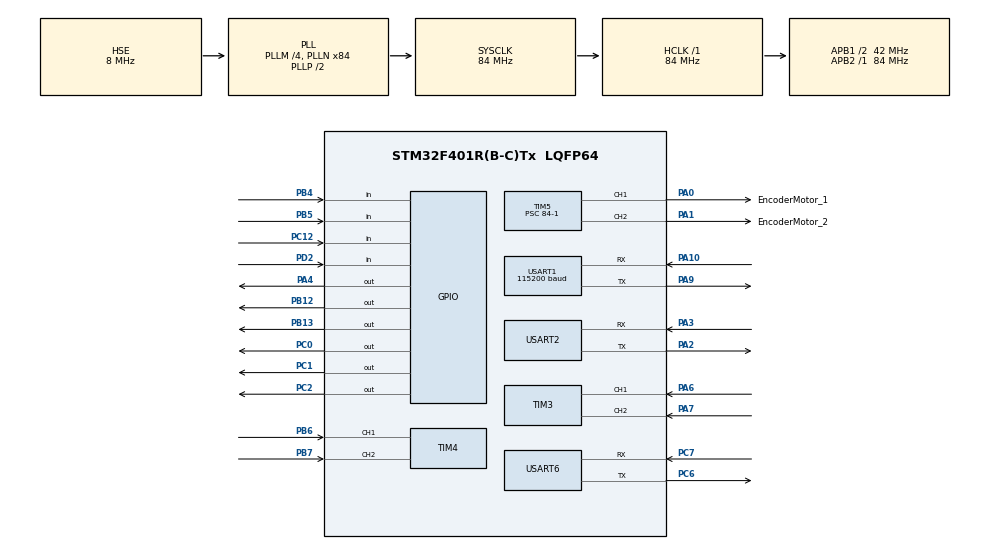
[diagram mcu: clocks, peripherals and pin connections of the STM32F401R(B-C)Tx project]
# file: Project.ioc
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Dma.Request0=USART2_RX
Dma.Request1=USART6_RX
Dma.Request2=USART1_RX
Dma.Request3=USART1_TX
Dma.USART1_RX.2.Direction=DMA_PERIPH_TO_MEMORY
Dma.USART1_RX.2.FIFOMode=DMA_FIFOMODE_DISABLE
Dma.USART1_RX.2.Instance=DMA2_Stream2
Dma.USART1_RX.2.MemDataAlignment=DMA_MDATAALIGN_BYTE
Dma.USART1_RX.2.MemInc=DMA_MINC_ENABLE
Dma.USART1_RX.2.Mode=DMA_NORMAL
Dma.USART1_RX.2.PeriphDataAlignment=DMA_PDATAALIGN_BYTE
Dma.USART1_RX.2.PeriphInc=DMA_PINC_DISABLE
Dma.USART1_RX.2.Priority=DMA_PRIORITY_LOW
Dma.USART1_TX.3.Direction=DMA_MEMORY_TO_PERIPH
Dma.USART1_TX.3.FIFOMode=DMA_FIFOMODE_DISABLE
Dma.USART1_TX.3.Instance=DMA2_Stream7
Dma.USART1_TX.3.MemDataAlignment=DMA_MDATAALIGN_BYTE
Dma.USART1_TX.3.MemInc=DMA_MINC_ENABLE
Dma.USART1_TX.3.Mode=DMA_NORMAL
Dma.USART1_TX.3.PeriphDataAlignment=DMA_PDATAALIGN_BYTE
Dma.USART1_TX.3.PeriphInc=DMA_PINC_DISABLE
Dma.USART1_TX.3.Priority=DMA_PRIORITY_LOW
Dma.USART2_RX.0.Direction=DMA_PERIPH_TO_MEMORY
Dma.USART2_RX.0.FIFOMode=DMA_FIFOMODE_DISABLE
Dma.USART2_RX.0.Instance=DMA1_Stream5
Dma.USART2_RX.0.MemDataAlignment=DMA_MDATAALIGN_BYTE
Dma.USART2_RX.0.MemInc=DMA_MINC_ENABLE
Dma.USART2_RX.0.Mode=DMA_NORMAL
Dma.USART2_RX.0.PeriphDataAlignment=DMA_PDATAALIGN_BYTE
Dma.USART2_RX.0.PeriphInc=DMA_PINC_DISABLE
Dma.USART2_RX.0.Priority=DMA_PRIORITY_LOW
Dma.USART6_RX.1.Direction=DMA_PERIPH_TO_MEMORY
Dma.USART6_RX.1.FIFOMode=DMA_FIFOMODE_DISABLE
Dma.USART6_RX.1.Instance=DMA2_Stream1
Dma.USART6_RX.1.MemDataAlignment=DMA_MDATAALIGN_BYTE
Dma.USART6_RX.1.MemInc=DMA_MINC_ENABLE
Dma.USART6_RX.1.Mode=DMA_NORMAL
Dma.USART6_RX.1.PeriphDataAlignment=DMA_PDATAALIGN_BYTE
Dma.USART6_RX.1.PeriphInc=DMA_PINC_DISABLE
Dma.USART6_RX.1.Priority=DMA_PRIORITY_LOW
FREERTOS.Tasks01=defaultTask,24,128,StartDefaultTask,Default,NULL,Dynamic,NULL,NULL
Mcu.Family=STM32F4
Mcu.Name=STM32F401R(B-C)Tx
Mcu.Package=LQFP64
NVIC.DMA1_Stream5_IRQn=true\:5\:0\:false\:false\:true\:true\:false\:true\:true
NVIC.DMA2_Stream1_IRQn=true\:5\:0\:false\:false\:true\:true\:false\:true\:true
NVIC.DMA2_Stream2_IRQn=true\:5\:0\:false\:false\:true\:true\:false\:true\:true
NVIC.DMA2_Stream7_IRQn=true\:5\:0\:false\:false\:true\:true\:false\:true\:true
NVIC.PriorityGroup=NVIC_PRIORITYGROUP_4
NVIC.TIM1_BRK_TIM9_IRQn=true\:5\:0\:false\:false\:true\:false\:false\:true\:true
NVIC.TIM1_TRG_COM_TIM11_IRQn=true\:5\:0\:false\:false\:true\:true\:true\:true\:true
NVIC.TimeBase=TIM1_BRK_TIM9_IRQn
NVIC.TimeBaseIP=TIM9
NVIC.USART1_IRQn=true\:5\:0\:false\:false\:true\:true\:true\:true\:true
NVIC.USART2_IRQn=true\:5\:0\:false\:false\:true\:true\:true\:true\:true
NVIC.USART6_IRQn=true\:5\:0\:false\:false\:true\:true\:true\:true\:true
PA0-WKUP.GPIO_Label=EncoderMotor_1
PA0-WKUP.Signal=S_TIM5_CH1
PA1.GPIO_Label=EncoderMotor_2
PA1.Signal=S_TIM5_CH2
PA10.Mode=Asynchronous
PA10.Signal=USART1_RX
PA13.Mode=Serial_Wire
PA13.Signal=SYS_JTMS-SWDIO
PA14.Mode=Serial_Wire
PA14.Signal=SYS_JTCK-SWCLK
PA2.Mode=Asynchronous
PA2.Signal=USART2_TX
PA3.Mode=Asynchronous
PA3.Signal=USART2_RX
PA4.Signal=GPIO_Output
PA6.Signal=S_TIM3_CH1
PA7.Signal=S_TIM3_CH2
PA9.Mode=Asynchronous
PA9.Signal=USART1_TX
PB12.GPIO_ModeDefaultOutputPP=GPIO_MODE_OUTPUT_OD
PB12.GPIO_PuPd=GPIO_NOPULL
PB12.GPIO_Speed=GPIO_SPEED_FREQ_MEDIUM
PB12.Signal=GPIO_Output
PB13.GPIO_ModeDefaultOutputPP=GPIO_MODE_OUTPUT_OD
PB13.GPIO_PuPd=GPIO_NOPULL
PB13.GPIO_Speed=GPIO_SPEED_FREQ_MEDIUM
PB13.Signal=GPIO_Output
PB4.GPIO_PuPd=GPIO_PULLUP
PB4.Signal=GPIO_Input
PB5.GPIO_PuPd=GPIO_PULLUP
PB5.Signal=GPIO_Input
PB6.Signal=S_TIM4_CH1
PB7.Signal=S_TIM4_CH2
PC0.Signal=GPIO_Output
PC1.Signal=GPIO_Output
PC12.GPIO_PuPd=GPIO_PULLUP
PC12.Signal=GPIO_Input
PC2.Signal=GPIO_Output
PC6.Mode=Asynchronous
PC6.Signal=USART6_TX
PC7.Mode=Asynchronous
PC7.Signal=USART6_RX
PD2.GPIO_PuPd=GPIO_PULLUP
PD2.Signal=GPIO_Input
PH0\ -\ OSC_IN.Mode=HSE-External-Oscillator
PH0\ -\ OSC_IN.Signal=RCC_OSC_IN
PH1\ -\ OSC_OUT.Mode=HSE-External-Oscillator
PH1\ -\ OSC_OUT.Signal=RCC_OSC_OUT
ProjectManager.HeapSize=0x200
ProjectManager.StackSize=0x400
ProjectManager.TargetToolchain=MDK-ARM V5.32
RCC.48MHZClocksFreq_Value=42000000
RCC.AHBFreq_Value=84000000
RCC.APB1CLKDivider=RCC_HCLK_DIV2
RCC.APB1Freq_Value=42000000
RCC.APB1TimFreq_Value=84000000
RCC.APB2Freq_Value=84000000
RCC.APB2TimFreq_Value=84000000
RCC.CortexFreq_Value=84000000
RCC.HCLKFreq_Value=84000000
RCC.HSE_VALUE=8000000
RCC.HSI_VALUE=16000000
RCC.LSE_VALUE=32768
RCC.PLLM=4
RCC.PLLN=84
RCC.PLLSourceVirtual=RCC_PLLSOURCE_HSE
RCC.SYSCLKFreq_VALUE=84000000
RCC.SYSCLKSource=RCC_SYSCLKSOURCE_PLLCLK
RCC.VCOOutputFreq_Value=168000000
SH.S_TIM3_CH1.0=TIM3_CH1,Encoder_Interface
SH.S_TIM3_CH2.0=TIM3_CH2,Encoder_Interface
SH.S_TIM4_CH1.0=TIM4_CH1,Encoder_Interface
SH.S_TIM4_CH2.0=TIM4_CH2,Encoder_Interface
SH.S_TIM5_CH1.0=TIM5_CH1,PWM Generation1 CH1
SH.S_TIM5_CH2.0=TIM5_CH2,PWM Generation2 CH2
TIM11.AutoReloadPreload=TIM_AUTORELOAD_PRELOAD_ENABLE
TIM11.Period=1000-1
TIM11.Prescaler=840-1
TIM3.AutoReloadPreload=TIM_AUTORELOAD_PRELOAD_ENABLE
TIM4.AutoReloadPreload=TIM_AUTORELOAD_PRELOAD_ENABLE
TIM5.Channel-PWM\ Generation1\ CH1=TIM_CHANNEL_1
TIM5.Channel-PWM\ Generation2\ CH2=TIM_CHANNEL_2
TIM5.Period=1000-1
TIM5.Prescaler=84-1
USART1.BaudRate=115200
USART1.VirtualMode=VM_ASYNC
USART2.VirtualMode=VM_ASYNC
USART6.VirtualMode=VM_ASYNC
VP_FREERTOS_VS_CMSIS_V2.Mode=CMSIS_V2
VP_SYS_VS_tim9.Mode=TIM9
VP_TIM11_VS_ClockSourceINT.Mode=Enable_Timer
VP_TIM5_VS_ClockSourceINT.Mode=Internal
board=custom

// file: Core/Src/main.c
/* USER CODE BEGIN Header */
/**
  ******************************************************************************
  * @file           : main.c
  * @brief          : Main program body
  ******************************************************************************
  * @attention
  *
  * Copyright (c) 2025 STMicroelectronics.
  * All rights reserved.
  *
  * This software is licensed under terms that can be found in the LICENSE file
  * in the root directory of this software component.
  * If no LICENSE file comes with this software, it is provided AS-IS.
  *
  ******************************************************************************
  */
/* USER CODE END Header */
#include "main.h"
#include "cmsis_os.h"
#include "dma.h"
#include "tim.h"
#include "usart.h"
#include "gpio.h"

/* USER CODE BEGIN Includes */
#include "receive_task.h"

/* USER CODE END Includes */

void SystemClock_Config(void);
void MX_FREERTOS_Init(void);

int main(void)
{

  /* MCU Configuration--------------------------------------------------------*/

  /* Reset of all peripherals, Initializes the Flash interface and the Systick. */
  HAL_Init();

  /* Configure the system clock */
  SystemClock_Config();

  /* Initialize all configured peripherals */
  MX_GPIO_Init();
  MX_DMA_Init();
  MX_USART1_UART_Init();
  MX_USART2_UART_Init();
  MX_USART6_UART_Init();
  MX_TIM5_Init();
  MX_TIM4_Init();
  MX_TIM3_Init();
  MX_TIM11_Init();
  /* USER CODE BEGIN 2 */
  receive_init();
  ecoMotor_init();
  OLED_Init();
  OLED_ShowString(0, 16, "Menu press Key1", OLED_6X8);
  OLED_Update();

  /* USER CODE END 2 */

  /* Init scheduler */
  osKernelInitialize();

  /* Call init function for freertos objects (in cmsis_os2.c) */
  MX_FREERTOS_Init();

  /* Start scheduler */
  osKernelStart();

  /* We should never get here as control is now taken by the scheduler */

  /* Infinite loop */
  while (1)
  {

  }
}

void SystemClock_Config(void)
{
  RCC_OscInitTypeDef RCC_OscInitStruct = {0};
  RCC_ClkInitTypeDef RCC_ClkInitStruct = {0};

  /** Configure the main internal regulator output voltage
  */
  __HAL_RCC_PWR_CLK_ENABLE();
  __HAL_PWR_VOLTAGESCALING_CONFIG(PWR_REGULATOR_VOLTAGE_SCALE2);

  /** Initializes the RCC Oscillators according to the specified parameters
  * in the RCC_OscInitTypeDef structure.
  */
  RCC_OscInitStruct.OscillatorType = RCC_OSCILLATORTYPE_HSE;
  RCC_OscInitStruct.HSEState = RCC_HSE_ON;
  RCC_OscInitStruct.PLL.PLLState = RCC_PLL_ON;
  RCC_OscInitStruct.PLL.PLLSource = RCC_PLLSOURCE_HSE;
  RCC_OscInitStruct.PLL.PLLM = 4;
  RCC_OscInitStruct.PLL.PLLN = 84;
  RCC_OscInitStruct.PLL.PLLP = RCC_PLLP_DIV2;
  RCC_OscInitStruct.PLL.PLLQ = 4;
  if (HAL_RCC_OscConfig(&RCC_OscInitStruct) != HAL_OK)
  {
    Error_Handler();
  }

  /** Initializes the CPU, AHB and APB buses clocks
  */
  RCC_ClkInitStruct.ClockType = RCC_CLOCKTYPE_HCLK|RCC_CLOCKTYPE_SYSCLK
                              |RCC_CLOCKTYPE_PCLK1|RCC_CLOCKTYPE_PCLK2;
  RCC_ClkInitStruct.SYSCLKSource = RCC_SYSCLKSOURCE_PLLCLK;
  RCC_ClkInitStruct.AHBCLKDivider = RCC_SYSCLK_DIV1;
  RCC_ClkInitStruct.APB1CLKDivider = RCC_HCLK_DIV2;
  RCC_ClkInitStruct.APB2CLKDivider = RCC_HCLK_DIV1;

  if (HAL_RCC_ClockConfig(&RCC_ClkInitStruct, FLASH_LATENCY_2) != HAL_OK)
  {
    Error_Handler();
  }
}

void HAL_TIM_PeriodElapsedCallback(TIM_HandleTypeDef *htim)
{
  /* USER CODE BEGIN Callback 0 */
    HAL_TIM_PeriodCallback_IT(htim);
  /* USER CODE END Callback 0 */
  if (htim->Instance == TIM9)
  {
    HAL_IncTick();
  }
}

void Error_Handler(void)
{
  __disable_irq();
  while (1)
  {
  }
}

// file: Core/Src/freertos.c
/* USER CODE BEGIN Header */
/**
  ******************************************************************************
  * File Name          : freertos.c
  * Description        : Code for freertos applications
  ******************************************************************************
  * @attention
  *
  * Copyright (c) 2025 STMicroelectronics.
  * All rights reserved.
  *
  * This software is licensed under terms that can be found in the LICENSE file
  * in the root directory of this software component.
  * If no LICENSE file comes with this software, it is provided AS-IS.
  *
  ******************************************************************************
  */
/* USER CODE END Header */

#include "FreeRTOS.h"
#include "task.h"
#include "main.h"
#include "cmsis_os.h"

/* USER CODE BEGIN Includes */
#include "receive_task.h"
/* USER CODE END Includes */

/* Definitions for defaultTask */
osThreadId_t defaultTaskHandle;
const osThreadAttr_t defaultTask_attributes = {
  .name = "defaultTask",
  .stack_size = 128 * 4,
  .priority = (osPriority_t) osPriorityNormal,
};

void StartDefaultTask(void *argument);

void MX_FREERTOS_Init(void); /* (MISRA C 2004 rule 8.1) */

void MX_FREERTOS_Init(void) {

  /* Create the thread(s) */
  /* creation of defaultTask */
  defaultTaskHandle = osThreadNew(StartDefaultTask, NULL, &defaultTask_attributes);

  /* USER CODE BEGIN RTOS_THREADS */
  /* add threads, ... */
  xTaskCreate(receive_Task, "receive_Task", 512, NULL, osPriorityNormal, &receive_task_handle);
  xTaskCreate(other_receive_TASk, "other_receive_TASk", 512, NULL, osPriorityNormal, &other_receive_TASk_handle);
  xTaskCreate(ecoMotor_Task, "ecoMotor_Task", 512, NULL, osPriorityNormal, &ecoMotor_Task_Handle);
  /* USER CODE END RTOS_THREADS */

}

void StartDefaultTask(void *argument)
{
  /* USER CODE BEGIN StartDefaultTask */
  /* Infinite loop */
  for(;;)
  {
    key_scan();
    KEY_LOG(1);
    osDelay(10);
  }
  /* USER CODE END StartDefaultTask */
}
